# STM32MP157x register map
File version: 1.3
Registers are 32-bit, read-write, reset 0x0 unless marked. A register's access mark holds for its fields unless they carry their own. Offsets are from the block's base; [hi:lo] are bit positions; {n}, {i} and the like mark numbered series.

## HDMI_CEC
Base 0x40016000
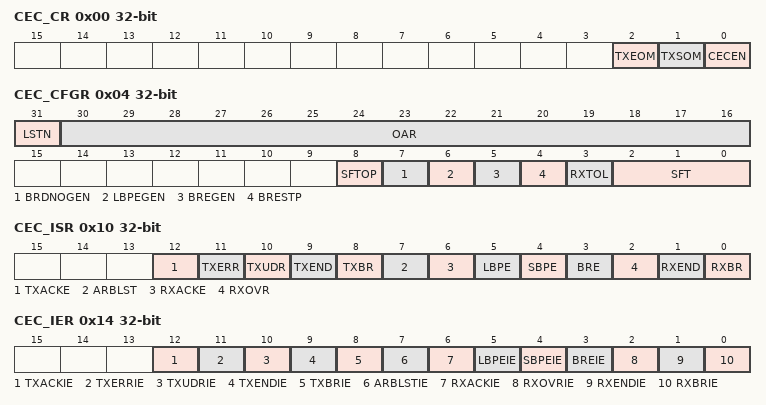
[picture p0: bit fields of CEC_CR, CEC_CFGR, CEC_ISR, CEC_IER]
0x00 CEC_CR — CEC control register
  [2] TXEOM, [1] TXSOM, [0] CECEN
0x04 CEC_CFGR — This register is used to configure the HDMI-CEC controller. It is mandatory to write CEC_CFGR only when CECEN=0.
  [31] LSTN, [30:16] OAR, [8] SFTOP, [7] BRDNOGEN, [6] LBPEGEN, [5] BREGEN, [4] BRESTP, [3] RXTOL, [2:0] SFT
0x08 CEC_TXDR — CEC Tx data register
  [7:0] TXD wo
0x0C CEC_RXDR ro — CEC Rx data register
  [7:0] RXD
0x10 CEC_ISR — CEC Interrupt and Status Register
  [12] TXACKE, [11] TXERR, [10] TXUDR, [9] TXEND, [8] TXBR, [7] ARBLST, [6] RXACKE, [5] LBPE, [4] SBPE, [3] BRE, [2] RXOVR, [1] RXEND, [0] RXBR
0x14 CEC_IER — CEC interrupt enable register
  [12] TXACKIE, [11] TXERRIE, [10] TXUDRIE, [9] TXENDIE, [8] TXBRIE, [7] ARBLSTIE, [6] RXACKIE, [5] LBPEIE, [4] SBPEIE, [3] BREIE, [2] RXOVRIE, [1] RXENDIE, [0] RXBRIE

## SPDIFRX
Base 0x4000D000
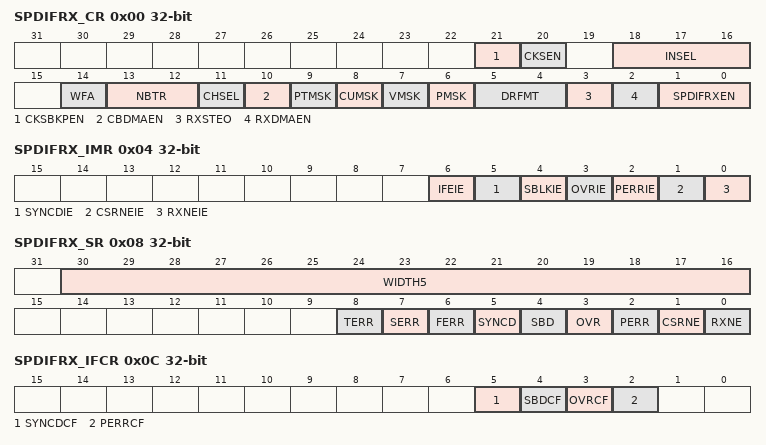
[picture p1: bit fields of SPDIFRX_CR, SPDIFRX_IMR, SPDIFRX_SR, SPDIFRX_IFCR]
0x00 SPDIFRX_CR — Control register
  [21] CKSBKPEN, [20] CKSEN, [18:16] INSEL, [14] WFA, [13:12] NBTR, [11] CHSEL, [10] CBDMAEN, [9] PTMSK, [8] CUMSK, [7] VMSK, [6] PMSK, [5:4] DRFMT, [3] RXSTEO, [2] RXDMAEN, [1:0] SPDIFRXEN
0x04 SPDIFRX_IMR — Interrupt mask register
  [6] IFEIE, [5] SYNCDIE, [4] SBLKIE, [3] OVRIE, [2] PERRIE, [1] CSRNEIE, [0] RXNEIE
0x08 SPDIFRX_SR ro — Status register
  [30:16] WIDTH5, [8] TERR, [7] SERR, [6] FERR, [5] SYNCD, [4] SBD, [3] OVR, [2] PERR, [1] CSRNE, [0] RXNE
0x0C SPDIFRX_IFCR — Interrupt flag clear register
  [5] SYNCDCF wo, [4] SBDCF wo, [3] OVRCF wo, [2] PERRCF wo
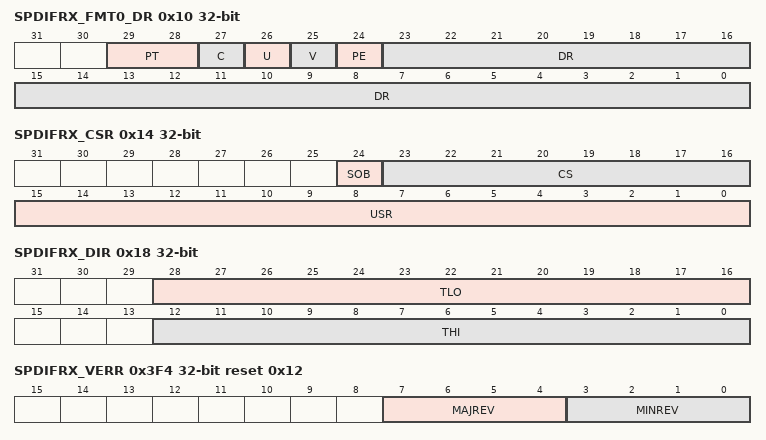
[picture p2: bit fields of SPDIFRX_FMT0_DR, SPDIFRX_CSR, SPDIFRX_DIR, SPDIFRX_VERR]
0x10 SPDIFRX_FMT0_DR ro — This register can take 3 different formats according to DRFMT. Here is the format when DRFMT = 00:
  [29:28] PT, [27] C, [26] U, [25] V, [24] PE, [23:0] DR
0x14 SPDIFRX_CSR ro — Channel status register
  [24] SOB, [23:16] CS, [15:0] USR
0x18 SPDIFRX_DIR ro — Debug information register
  [28:16] TLO, [12:0] THI
0x3F4 SPDIFRX_VERR ro reset 0x12 — SPDIFRX version register
  [7:4] MAJREV, [3:0] MINREV
0x3F8 SPDIFRX_IPIDR ro reset 0x130041 — SPDIFRX identification register
  [31:0] ID
0x3FC SPDIFRX_SIDR ro reset 0xA3C5DD01 — SPDIFRX size identification register
  [31:0] SID

## WWDG1
Base 0x4000A000
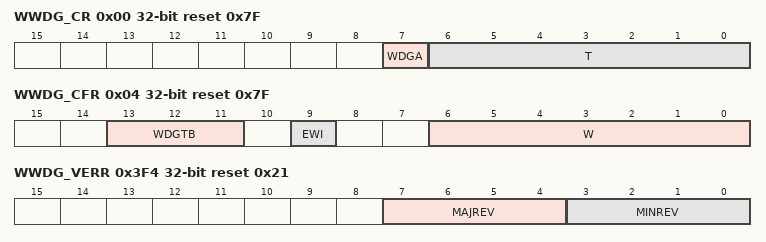
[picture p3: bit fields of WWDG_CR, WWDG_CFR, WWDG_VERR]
0x00 WWDG_CR reset 0x7F — Control register
  [7] WDGA, [6:0] T
0x04 WWDG_CFR reset 0x7F — Configuration register
  [13:11] WDGTB, [9] EWI, [6:0] W
0x08 WWDG_SR — Status register
  [0] EWIF
0x3F0 WWDG_HWCFGR ro reset 0xFFF — WWDG hardware configuration register
  [15:0] PREDIV
0x3F4 WWDG_VERR ro reset 0x21 — WWDG version register
  [7:4] MAJREV, [3:0] MINREV
0x3F8 WWDG_IPIDR ro reset 0x120051 — WWDG ID register
  [31:0] ID
0x3FC WWDG_SIDR ro reset 0xA3C5DD01 — WWDG size ID register
  [31:0] SID

## TIM15
Base 0x44006000
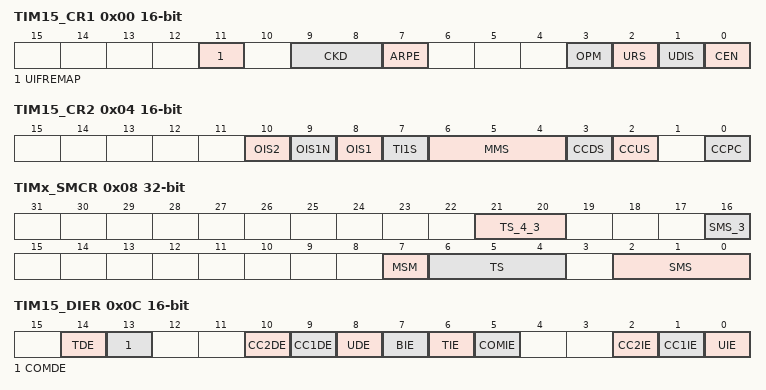
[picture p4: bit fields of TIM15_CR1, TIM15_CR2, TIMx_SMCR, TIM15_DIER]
0x00 TIM15_CR1 16-bit — TIM15 control register 1
  [11] UIFREMAP, [9:8] CKD, [7] ARPE, [3] OPM, [2] URS, [1] UDIS, [0] CEN
0x04 TIM15_CR2 16-bit — TIM15 control register 2
  [10] OIS2, [9] OIS1N, [8] OIS1, [7] TI1S, [6:4] MMS, [3] CCDS, [2] CCUS, [0] CCPC
0x08 TIMx_SMCR — slave mode control register
  [21:20] TS_4_3 — Trigger selection
  [16] SMS_3 — Slave mode selection - bit 3
  [7] MSM — Master/Slave mode
  [6:4] TS — Trigger selection
  [2:0] SMS — Slave mode selection
0x0C TIM15_DIER 16-bit — TIM15 DMA/interrupt enable register
  [14] TDE, [13] COMDE, [10] CC2DE, [9] CC1DE, [8] UDE, [7] BIE, [6] TIE, [5] COMIE, [2] CC2IE, [1] CC1IE, [0] UIE
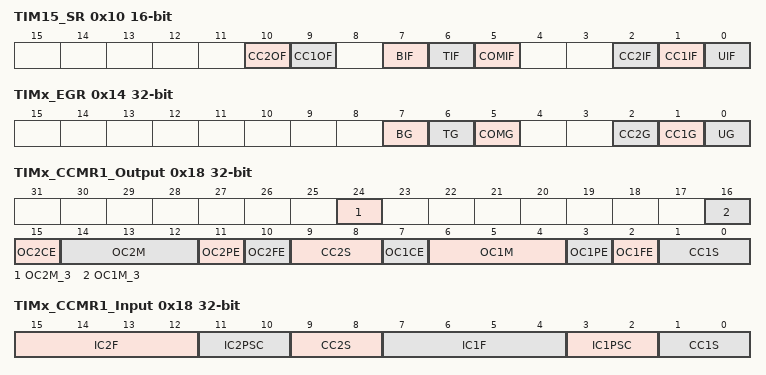
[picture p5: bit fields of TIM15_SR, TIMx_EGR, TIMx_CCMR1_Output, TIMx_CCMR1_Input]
0x10 TIM15_SR 16-bit — TIM15 status register
  [10] CC2OF, [9] CC1OF, [7] BIF, [6] TIF, [5] COMIF, [2] CC2IF, [1] CC1IF, [0] UIF
0x14 TIMx_EGR wo — event generation register
  [7] BG
  [6] TG — Trigger generation
  [5] COMG
  [2] CC2G — Capture/compare 2 generation
  [1] CC1G — Capture/compare 1 generation
  [0] UG — Update generation
0x18 TIMx_CCMR1_Output — capture/compare mode register 1 (output mode)
  [24] OC2M_3 — Output Compare 2 mode - bit 3
  [16] OC1M_3 — Output Compare 1 mode - bit 3
  [15] OC2CE — Output compare 2 clear enable
  [14:12] OC2M — Output compare 2 mode
  [11] OC2PE — Output compare 2 preload enable
  [10] OC2FE — Output compare 2 fast enable
  [9:8] CC2S — Capture/Compare 2 selection
  [7] OC1CE — Output compare 1 clear enable
  [6:4] OC1M — Output compare 1 mode
  [3] OC1PE — Output compare 1 preload enable
  [2] OC1FE — Output compare 1 fast enable
  [1:0] CC1S — Capture/Compare 1 selection
0x18 TIMx_CCMR1_Input (alternate view of TIMx_CCMR1_Output) — capture/compare mode register 1 (input mode)
  [15:12] IC2F — Input capture 2 filter
  [11:10] IC2PSC — Input capture 2 prescaler
  [9:8] CC2S — Capture/compare 2 selection
  [7:4] IC1F — Input capture 1 filter
  [3:2] IC1PSC — Input capture 1 prescaler
  [1:0] CC1S — Capture/Compare 1 selection
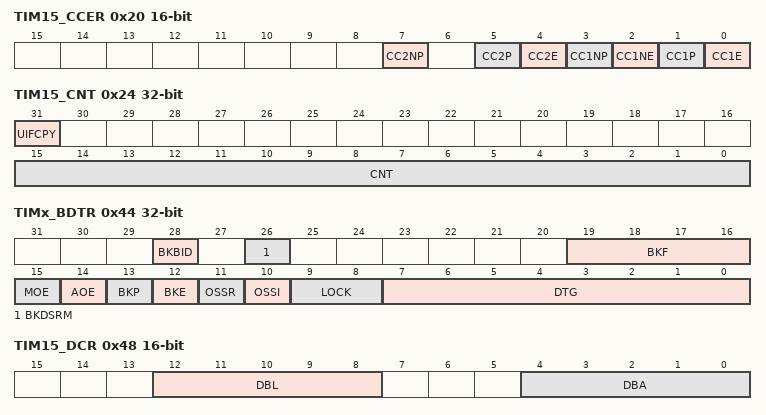
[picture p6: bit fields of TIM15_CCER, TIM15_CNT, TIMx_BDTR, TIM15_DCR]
0x20 TIM15_CCER 16-bit — TIM15 capture/compare enable register
  [7] CC2NP, [5] CC2P, [4] CC2E, [3] CC1NP, [2] CC1NE, [1] CC1P, [0] CC1E
0x24 TIM15_CNT — TIM15 counter
  [31] UIFCPY ro, [15:0] CNT
0x28 TIM15_PSC 16-bit — TIM15 prescaler
0x2C TIM15_ARR 16-bit reset 0xFFFF — TIM15 auto-reload register
0x30 TIM15_RCR 16-bit — TIM15 repetition counter register
  [7:0] REP
0x34 TIM15_CCR1 16-bit — TIM15 capture/compare register 1
0x38 TIM15_CCR2 16-bit — TIM15 capture/compare register 2
0x44 TIMx_BDTR — As the bits BK2BID, BKBID, BK2DSRM, BKDSRM, BK2P, BK2E, BK2F[3:0], BKF[3:0], AOE, BKP, BKE, OSSI, OSSR and DTG[7:0] can be write-locked depending on the LOCK configuration, it can be necessary to configure all of them during the first write access to the TIMx_BDTR register.
  [28] BKBID, [26] BKDSRM, [19:16] BKF, [15] MOE, [14] AOE, [13] BKP, [12] BKE, [11] OSSR, [10] OSSI, [9:8] LOCK, [7:0] DTG
0x48 TIM15_DCR 16-bit — TIM15 DMA control register
  [12:8] DBL, [4:0] DBA
0x4C TIM15_DMAR 16-bit — TIM15 DMA address for full transfer
  [15:0] DMAB
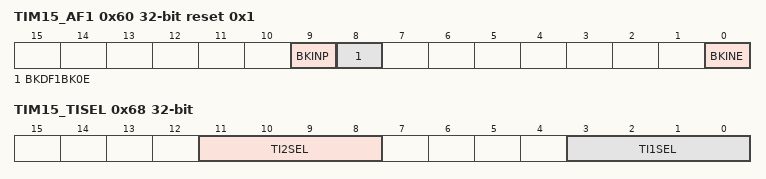
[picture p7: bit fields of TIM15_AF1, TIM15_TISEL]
0x60 TIM15_AF1 reset 0x1 — TIM15 alternate register 1
  [9] BKINP, [8] BKDF1BK0E, [0] BKINE
0x68 TIM15_TISEL — TIM15 input selection register
  [11:8] TI2SEL, [3:0] TI1SEL

## TIM16
Base 0x44007000
Same registers: TIM17 0x44008000
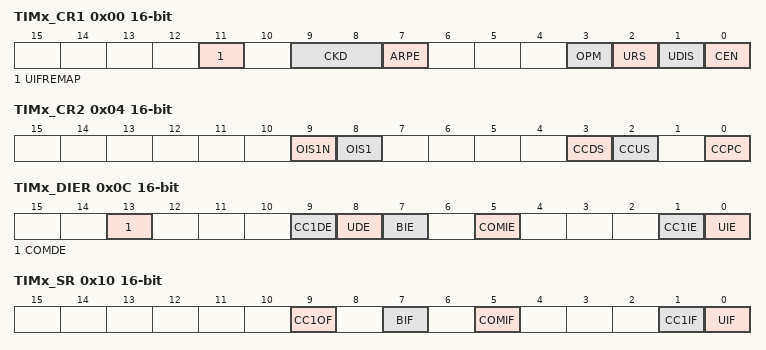
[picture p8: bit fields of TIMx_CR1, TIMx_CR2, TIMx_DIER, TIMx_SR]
0x00 TIMx_CR1 16-bit — TIM16/TIM17 control register 1
  [11] UIFREMAP, [9:8] CKD, [7] ARPE, [3] OPM, [2] URS, [1] UDIS, [0] CEN
0x04 TIMx_CR2 16-bit — TIM16/TIM17 control register 2
  [9] OIS1N, [8] OIS1, [3] CCDS, [2] CCUS, [0] CCPC
0x0C TIMx_DIER 16-bit — TIM16/TIM17 DMA/interrupt enable register
  [13] COMDE, [9] CC1DE, [8] UDE, [7] BIE, [5] COMIE, [1] CC1IE, [0] UIE
0x10 TIMx_SR 16-bit — TIM16/TIM17 status register
  [9] CC1OF, [7] BIF, [5] COMIF, [1] CC1IF, [0] UIF
0x14 TIMx_EGR wo — event generation register
  [0] UG — Update generation
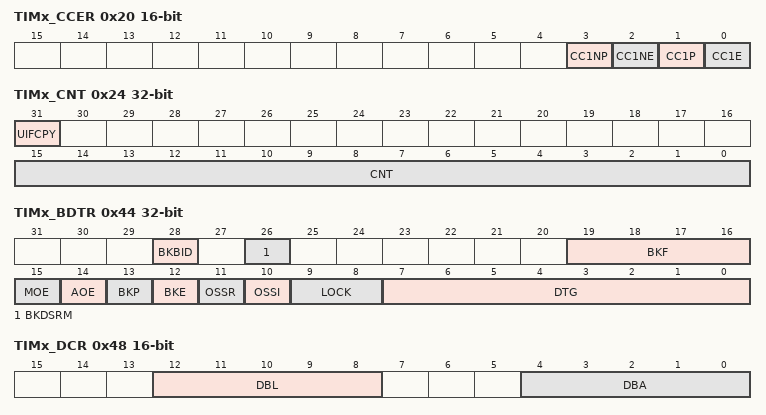
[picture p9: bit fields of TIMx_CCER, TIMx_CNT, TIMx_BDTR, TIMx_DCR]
0x20 TIMx_CCER 16-bit — TIM16/TIM17 capture/compare enable register
  [3] CC1NP, [2] CC1NE, [1] CC1P, [0] CC1E
0x24 TIMx_CNT — TIM16/TIM17 counter
  [31] UIFCPY ro, [15:0] CNT
0x28 TIMx_PSC 16-bit — TIM16/TIM17 prescaler
0x2C TIMx_ARR 16-bit reset 0xFFFF — TIM16/TIM17 auto-reload register
0x30 TIMx_RCR 16-bit — TIM16/TIM17 repetition counter register
  [7:0] REP
0x34 TIMx_CCR1 16-bit — TIM16/TIM17 capture/compare register 1
0x44 TIMx_BDTR — As the BKBID, BKDSRM, BKF[3:0], AOE, BKP, BKE, OSSI, OSSR and DTG[7:0] bits may be write-locked depending on the LOCK configuration, it may be necessary to configure all of them during the first write access to the TIMx_BDTR register.
  [28] BKBID, [26] BKDSRM, [19:16] BKF, [15] MOE, [14] AOE, [13] BKP, [12] BKE, [11] OSSR, [10] OSSI, [9:8] LOCK, [7:0] DTG
0x48 TIMx_DCR 16-bit — TIM16/TIM17 DMA control register
  [12:8] DBL, [4:0] DBA
0x4C TIMx_DMAR 16-bit — TIM16/TIM17 DMA address for full transfer
  [15:0] DMAB
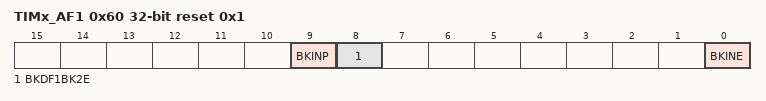
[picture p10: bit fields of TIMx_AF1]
0x60 TIMx_AF1 reset 0x1 — TIM17 alternate function register 1
  [9] BKINP, [8] BKDF1BK2E, [0] BKINE
0x68 TIMx_TISEL — TIM17 input selection register
  [3:0] TI1SEL

## NVIC — Nested Vectored Interrupt Controller
Base 0xE000E100
{0x0+4i} ISER{i} (i=0..3) — Interrupt Set-Enable Register
  [31:0] SETENA
0x10 ISER4 — Interrupt Set-Enable Register
{0x80+4i} ICER{i} (i=0..3) — Interrupt Clear-Enable Register
  [31:0] CLRENA
0x90 ICER4 — Interrupt Clear-Enable Register
{0x100+4i} ISPR{i} (i=0..3) — Interrupt Set-Pending Register
  [31:0] SETPEND
0x110 ISPR4 — Interrupt Set-Pending Register
{0x180+4i} ICPR{i} (i=0..3) — Interrupt Clear-Pending Register
  [31:0] CLRPEND
0x1C4 ICPR4 — Interrupt Clear-Pending Register
{0x200+4i} IABR{i} ro (i=0..3) — Interrupt Active Bit Register
  [31:0] ACTIVE
0x210 IABR4 — Interrupt Active Bit Register
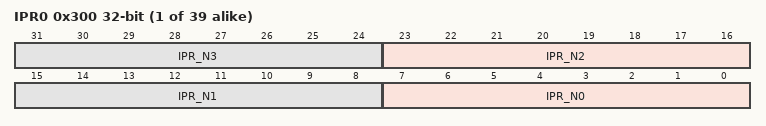
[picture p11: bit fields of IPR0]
{0x300+4i} IPR{i} (i=0..38) — Interrupt Priority Register
  [8n+7:8n] IPR_N{n} (n=0..3)
